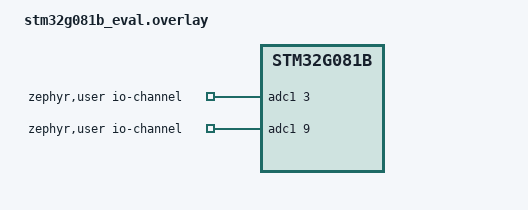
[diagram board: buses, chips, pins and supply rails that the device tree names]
/*
 * SPDX-License-Identifier: Apache-2.0
 *
 * Copyright (c) 2023 STMicroelectronics
 */

/ {
	zephyr,user {
		/* adjust channel number according to pinmux in board.dts */
		io-channels = <&adc1 3>, <&adc1 9>;
	};
};
